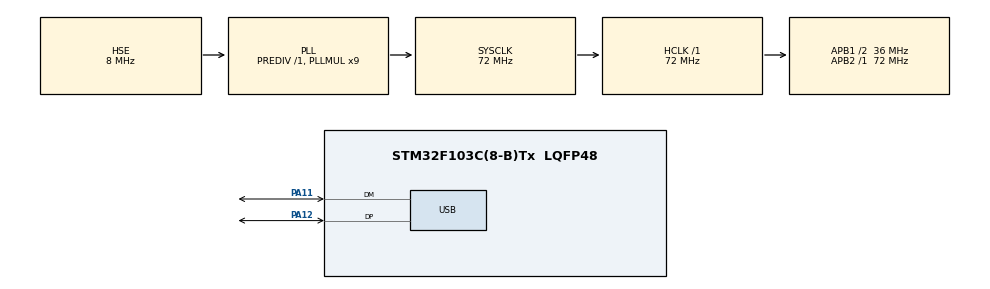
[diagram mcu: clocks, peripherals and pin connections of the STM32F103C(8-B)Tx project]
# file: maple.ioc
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FREERTOS.INCLUDE_pcTaskGetTaskName=1
FREERTOS.INCLUDE_vTaskCleanUpResources=1
FREERTOS.INCLUDE_xEventGroupSetBitFromISR=1
FREERTOS.INCLUDE_xSemaphoreGetMutexHolder=1
FREERTOS.INCLUDE_xTaskAbortDelay=1
FREERTOS.INCLUDE_xTaskGetCurrentTaskHandle=1
FREERTOS.INCLUDE_xTaskGetHandle=1
FREERTOS.Tasks01=defaultTask,24,128,StartDefaultTask,Default,NULL,Dynamic,NULL,NULL;myTask02,12,512,StartTask02,Default,NULL,Dynamic,NULL,NULL;myTask03,8,512,StartTask03,Default,NULL,Dynamic,NULL,NULL
FREERTOS.configTOTAL_HEAP_SIZE=8192
FREERTOS.configUSE_NEWLIB_REENTRANT=1
Mcu.Family=STM32F1
Mcu.Name=STM32F103C(8-B)Tx
Mcu.Package=LQFP48
NVIC.PriorityGroup=NVIC_PRIORITYGROUP_4
NVIC.TIM2_IRQn=true\:15\:0\:false\:false\:true\:false\:false\:true\:true
NVIC.TimeBase=TIM2_IRQn
NVIC.TimeBaseIP=TIM2
NVIC.USB_LP_CAN1_RX0_IRQn=true\:5\:0\:false\:false\:true\:true\:false\:true\:true
PA11.Mode=Device
PA11.Signal=USB_DM
PA12.Mode=Device
PA12.Signal=USB_DP
PA13.Mode=JTAG_5_pins
PA13.Signal=SYS_JTMS-SWDIO
PA14.Mode=JTAG_5_pins
PA14.Signal=SYS_JTCK-SWCLK
PA15.Mode=JTAG_5_pins
PA15.Signal=SYS_JTDI
PB3.Mode=JTAG_5_pins
PB3.Signal=SYS_JTDO-TRACESWO
PB4.Mode=JTAG_5_pins
PB4.Signal=SYS_NJTRST
PD0-OSC_IN.Mode=HSE-External-Oscillator
PD0-OSC_IN.Signal=RCC_OSC_IN
PD1-OSC_OUT.Mode=HSE-External-Oscillator
PD1-OSC_OUT.Signal=RCC_OSC_OUT
ProjectManager.HeapSize=0x200
ProjectManager.StackSize=0x400
ProjectManager.TargetToolchain=STM32CubeIDE
RCC.AHBFreq_Value=72000000
RCC.APB1CLKDivider=RCC_HCLK_DIV2
RCC.APB1Freq_Value=36000000
RCC.APB1TimFreq_Value=72000000
RCC.APB2Freq_Value=72000000
RCC.APB2TimFreq_Value=72000000
RCC.HCLKFreq_Value=72000000
RCC.PLLMUL=RCC_PLL_MUL9
RCC.SYSCLKFreq_VALUE=72000000
RCC.SYSCLKSource=RCC_SYSCLKSOURCE_PLLCLK
RCC.USBFreq_Value=48000000
RCC.USBPrescaler=RCC_USBCLKSOURCE_PLL_DIV1_5
USB_DEVICE.CLASS_NAME_FS=CDC
USB_DEVICE.VirtualMode=Cdc
USB_DEVICE.VirtualModeFS=Cdc_FS
VP_FREERTOS_VS_CMSIS_V2.Mode=CMSIS_V2
VP_SYS_VS_tim2.Mode=TIM2
VP_USB_DEVICE_VS_USB_DEVICE_CDC_FS.Mode=CDC_FS
board=custom

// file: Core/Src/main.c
/* USER CODE BEGIN Header */
/**
  ******************************************************************************
  * @file           : main.c
  * @brief          : Main program body
  ******************************************************************************
  * @attention
  *
  * Copyright (c) 2023 STMicroelectronics.
  * All rights reserved.
  *
  * This software is licensed under terms that can be found in the LICENSE file
  * in the root directory of this software component.
  * If no LICENSE file comes with this software, it is provided AS-IS.
  *
  ******************************************************************************
  */
/* USER CODE END Header */
#include "main.h"
#include "cmsis_os.h"
#include "usb_device.h"

/* Definitions for defaultTask */
osThreadId_t defaultTaskHandle;
const osThreadAttr_t defaultTask_attributes = {
  .name = "defaultTask",
  .stack_size = 128 * 4,
  .priority = (osPriority_t) osPriorityNormal,
};
/* Definitions for myTask02 */
osThreadId_t myTask02Handle;
const osThreadAttr_t myTask02_attributes = {
  .name = "myTask02",
  .stack_size = 128 * 4,
  .priority = (osPriority_t) osPriorityLow4,
};
/* Definitions for myTask03 */
osThreadId_t myTask03Handle;
const osThreadAttr_t myTask03_attributes = {
  .name = "myTask03",
  .stack_size = 128 * 4,
  .priority = (osPriority_t) osPriorityLow,
};

void SystemClock_Config(void);
static void MX_GPIO_Init(void);
void StartDefaultTask(void *argument);
void StartTask02(void *argument);
void StartTask03(void *argument);

int main(void)
{

  /* MCU Configuration--------------------------------------------------------*/

  /* Reset of all peripherals, Initializes the Flash interface and the Systick. */
  HAL_Init();

  /* Configure the system clock */
  SystemClock_Config();

  /* Initialize all configured peripherals */
  MX_GPIO_Init();
  /* USER CODE BEGIN 2 */

  SEGGER_SYSVIEW_Conf();

  /* USER CODE END 2 */

  /* Init scheduler */
  osKernelInitialize();

  /* Create the thread(s) */
  /* creation of defaultTask */
  defaultTaskHandle = osThreadNew(StartDefaultTask, NULL, &defaultTask_attributes);

  /* creation of myTask02 */
  myTask02Handle = osThreadNew(StartTask02, NULL, &myTask02_attributes);

  /* creation of myTask03 */
  myTask03Handle = osThreadNew(StartTask03, NULL, &myTask03_attributes);

  /* Start scheduler */
  osKernelStart();
  /* We should never get here as control is now taken by the scheduler */
  /* Infinite loop */
  while (1)
  {

  }
}

void SystemClock_Config(void)
{
  RCC_OscInitTypeDef RCC_OscInitStruct = {0};
  RCC_ClkInitTypeDef RCC_ClkInitStruct = {0};
  RCC_PeriphCLKInitTypeDef PeriphClkInit = {0};

  /** Initializes the RCC Oscillators according to the specified parameters
  * in the RCC_OscInitTypeDef structure.
  */
  RCC_OscInitStruct.OscillatorType = RCC_OSCILLATORTYPE_HSE;
  RCC_OscInitStruct.HSEState = RCC_HSE_ON;
  RCC_OscInitStruct.HSEPredivValue = RCC_HSE_PREDIV_DIV1;
  RCC_OscInitStruct.HSIState = RCC_HSI_ON;
  RCC_OscInitStruct.PLL.PLLState = RCC_PLL_ON;
  RCC_OscInitStruct.PLL.PLLSource = RCC_PLLSOURCE_HSE;
  RCC_OscInitStruct.PLL.PLLMUL = RCC_PLL_MUL9;
  if (HAL_RCC_OscConfig(&RCC_OscInitStruct) != HAL_OK)
  {
    Error_Handler();
  }

  /** Initializes the CPU, AHB and APB buses clocks
  */
  RCC_ClkInitStruct.ClockType = RCC_CLOCKTYPE_HCLK|RCC_CLOCKTYPE_SYSCLK
                              |RCC_CLOCKTYPE_PCLK1|RCC_CLOCKTYPE_PCLK2;
  RCC_ClkInitStruct.SYSCLKSource = RCC_SYSCLKSOURCE_PLLCLK;
  RCC_ClkInitStruct.AHBCLKDivider = RCC_SYSCLK_DIV1;
  RCC_ClkInitStruct.APB1CLKDivider = RCC_HCLK_DIV2;
  RCC_ClkInitStruct.APB2CLKDivider = RCC_HCLK_DIV1;

  if (HAL_RCC_ClockConfig(&RCC_ClkInitStruct, FLASH_LATENCY_2) != HAL_OK)
  {
    Error_Handler();
  }
  PeriphClkInit.PeriphClockSelection = RCC_PERIPHCLK_USB;
  PeriphClkInit.UsbClockSelection = RCC_USBCLKSOURCE_PLL_DIV1_5;
  if (HAL_RCCEx_PeriphCLKConfig(&PeriphClkInit) != HAL_OK)
  {
    Error_Handler();
  }
}

static void MX_GPIO_Init(void)
{

  /* GPIO Ports Clock Enable */
  __HAL_RCC_GPIOD_CLK_ENABLE();
  __HAL_RCC_GPIOA_CLK_ENABLE();
  __HAL_RCC_GPIOB_CLK_ENABLE();

}

void StartDefaultTask(void *argument)
{
  /* init code for USB_DEVICE */
  MX_USB_DEVICE_Init();
  for(;;)
  {
    osDelay(1);
  }
}

void StartTask02(void *argument)
{
  for(;;)
  {
    osDelay(1);
  }
}

void StartTask03(void *argument)
{
  for(;;)
  {
    osDelay(1);
  }
}

void HAL_TIM_PeriodElapsedCallback(TIM_HandleTypeDef *htim)
{
  if (htim->Instance == TIM2) {
    HAL_IncTick();
  }
}

void Error_Handler(void)
{
  __disable_irq();
  while (1)
  {
  }
}
